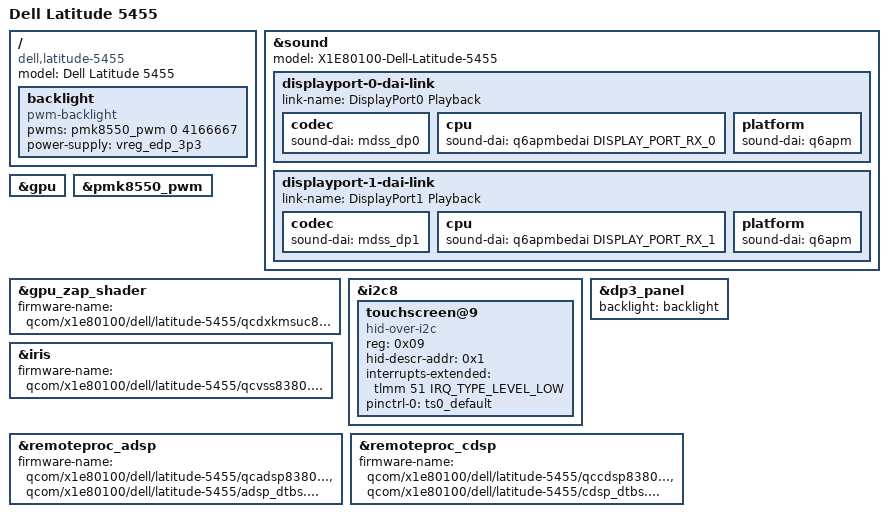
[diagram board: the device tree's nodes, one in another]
// SPDX-License-Identifier: BSD-3-Clause
/*
 * Copyright (c) 2025 Val Packett <val@packett.cool>
 */
/dts-v1/;

#include "hamoa.dtsi"
#include "x1-dell-thena.dtsi"

/ {
	model = "Dell Latitude 5455";
	compatible = "dell,latitude-5455", "qcom,x1e80100";

	backlight: backlight {
		compatible = "pwm-backlight";
		pwms = <&pmk8550_pwm 0 4166667>;

		power-supply = <&vreg_edp_3p3>;
	};
};

&sound {
	model = "X1E80100-Dell-Latitude-5455";

	displayport-0-dai-link {
		link-name = "DisplayPort0 Playback";

		codec {
			sound-dai = <&mdss_dp0>;
		};

		cpu {
			sound-dai = <&q6apmbedai DISPLAY_PORT_RX_0>;
		};

		platform {
			sound-dai = <&q6apm>;
		};
	};

	displayport-1-dai-link {
		link-name = "DisplayPort1 Playback";

		codec {
			sound-dai = <&mdss_dp1>;
		};

		cpu {
			sound-dai = <&q6apmbedai DISPLAY_PORT_RX_1>;
		};

		platform {
			sound-dai = <&q6apm>;
		};
	};
};


&gpu {
	status = "okay";
};

&pmk8550_pwm {
        status = "okay";
};

&gpu_zap_shader {
	firmware-name = "qcom/x1e80100/dell/latitude-5455/qcdxkmsuc8380.mbn";
};

&i2c8 {
	/* LXST2021 */
	touchscreen@9 {
		compatible = "hid-over-i2c";
		reg = <0x09>;

		hid-descr-addr = <0x1>;
		interrupts-extended = <&tlmm 51 IRQ_TYPE_LEVEL_LOW>;

		pinctrl-0 = <&ts0_default>;
		pinctrl-names = "default";
	};
};

&iris {
	firmware-name = "qcom/x1e80100/dell/latitude-5455/qcvss8380.mbn";
	status = "okay";
};

&dp3_panel {
	backlight = <&backlight>;
};

&remoteproc_adsp {
	firmware-name = "qcom/x1e80100/dell/latitude-5455/qcadsp8380.mbn",
			"qcom/x1e80100/dell/latitude-5455/adsp_dtbs.elf";

	status = "okay";
};

&remoteproc_cdsp {
	firmware-name = "qcom/x1e80100/dell/latitude-5455/qccdsp8380.mbn",
			"qcom/x1e80100/dell/latitude-5455/cdsp_dtbs.elf";

	status = "okay";
};
